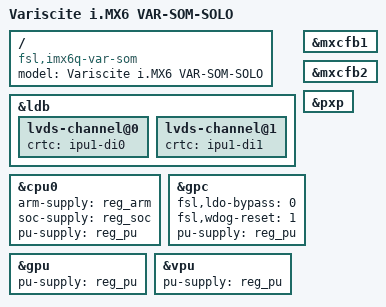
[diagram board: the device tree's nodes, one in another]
/*
 * Copyright (C) 2013 Freescale Semiconductor, Inc.
 *
 * This program is free software; you can redistribute it and/or modify
 * it under the terms of the GNU General Public License version 2 as
 * published by the Free Software Foundation.
 */

/dts-v1/;

#define VAR_SOM_MX6

#include "imx6dl.dtsi"
#include "imx6qdl-var-som.dtsi"

/ {
	model = "Variscite i.MX6 VAR-SOM-SOLO";
	compatible = "fsl,imx6q-var-som", "fsl,imx6q";
};



&ldb {
	lvds-channel@0 {
		crtc = "ipu1-di0";
	};
	lvds-channel@1 {
		crtc = "ipu1-di1";
	};
};
&mxcfb1 {
	status = "okay";
};

&mxcfb2 {
	status = "okay";
};

&pxp {
	status = "okay";
};


&cpu0 {

	arm-supply = <&reg_arm>;
	soc-supply = <&reg_soc>;
	pu-supply = <&reg_pu>; /* use pu_dummy if VDDSOC share with VDDPU */
};

&gpc {
	fsl,ldo-bypass = <0>; /* use ldo-bypass, u-boot will check it and configure */
	fsl,wdog-reset = <1>; /* watchdog select of reset source */
	pu-supply = <&reg_pu>; /* ldo-bypass:use pu_dummy if VDDSOC share with VDDPU */
};

&gpu {
	pu-supply = <&reg_pu>; /* ldo-bypass:use pu_dummy if VDDSOC share with VDDPU */
};

&vpu {
	pu-supply = <&reg_pu>; /* ldo-bypass:use pu_dummy if VDDSOC share with VDDPU */
};
